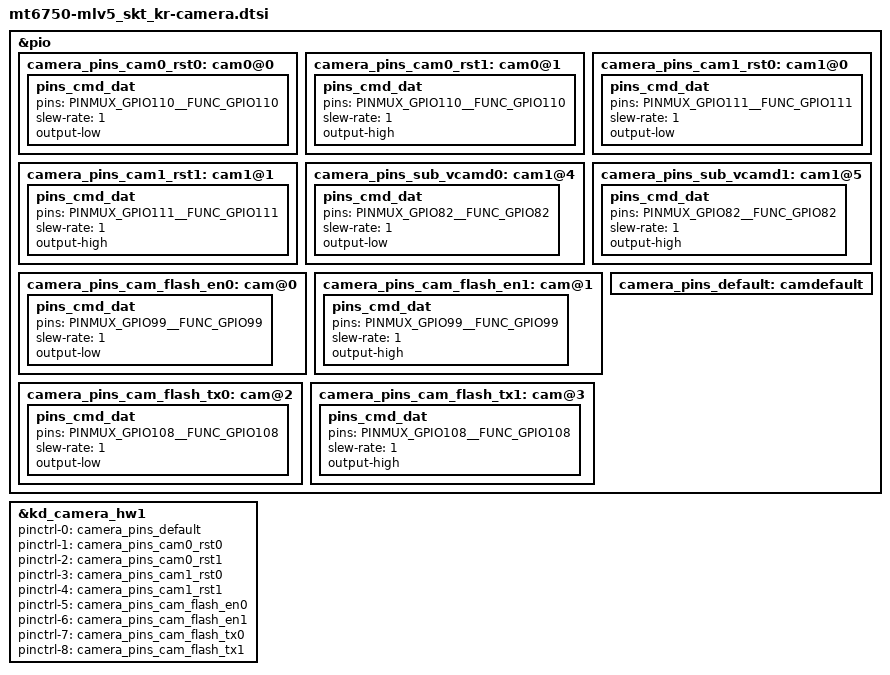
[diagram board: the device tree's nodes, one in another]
/*
 * LG Electronics LV5 usb device tree source
 *
 * Copyright (c) 2016 LG Electronics Co., Ltd.
 *              http://www.lge.com
 *
 */

/* CAMERA GPIO standardization */
&pio {
	camera_pins_cam0_rst0: cam0@0 {
	    pins_cmd_dat {
			pins = <PINMUX_GPIO110__FUNC_GPIO110>;
			slew-rate = <1>; /*direction 0:in, 1:out*/
			output-low;/*direction out used only. output_low or high*/
		};
	};
	camera_pins_cam0_rst1: cam0@1 {
	    pins_cmd_dat {
			pins = <PINMUX_GPIO110__FUNC_GPIO110>;
			slew-rate = <1>;
			output-high;
		};
	};
	camera_pins_cam1_rst0: cam1@0 {
	    pins_cmd_dat {
			pins = <PINMUX_GPIO111__FUNC_GPIO111>;
			slew-rate = <1>; /*direction 0:in, 1:out*/
			output-low;/*direction out used only. output_low or high*/
		};
	};
	camera_pins_cam1_rst1: cam1@1 {
	    pins_cmd_dat {
			pins = <PINMUX_GPIO111__FUNC_GPIO111>;
			slew-rate = <1>;
			output-high;
		};
	};
	camera_pins_sub_vcamd0: cam1@4 {
		pins_cmd_dat {
			pins = <PINMUX_GPIO82__FUNC_GPIO82>;
			slew-rate = <1>;
			output-low;
		};
	};
	camera_pins_sub_vcamd1: cam1@5 {
		pins_cmd_dat {
			pins = <PINMUX_GPIO82__FUNC_GPIO82>;
			slew-rate = <1>;
			output-high;
		};
	};
	camera_pins_cam_flash_en0: cam@0 {
	    pins_cmd_dat {
			pins = <PINMUX_GPIO99__FUNC_GPIO99>;/*GPIO_CAMERA_FLASH_EN_PIN*/
			slew-rate = <1>; /*direction 0:in, 1:out*/
			output-low;/*direction out used only. output_low or high*/
		};
	};
	camera_pins_cam_flash_en1: cam@1 {
	    pins_cmd_dat {
			pins = <PINMUX_GPIO99__FUNC_GPIO99>;/*GPIO_CAMERA_FLASH_EN_PIN*/
			slew-rate = <1>; /*direction 0:in, 1:out*/
			output-high;
		};
	};
	camera_pins_cam_flash_tx0: cam@2 {
	    pins_cmd_dat {
			pins = <PINMUX_GPIO108__FUNC_GPIO108>;/*GPIO_CAMERA_FLASH_TX_PIN*/
			slew-rate = <1>; /*direction 0:in, 1:out*/
			output-low;/*direction out used only. output_low or high*/
		};
	};
	camera_pins_cam_flash_tx1: cam@3 {
	    pins_cmd_dat {
			pins = <PINMUX_GPIO108__FUNC_GPIO108>;/*GPIO_CAMERA_FLASH_TX_PIN*/
			slew-rate = <1>; /*direction 0:in, 1:out*/
			output-high;/*direction out used only. output_low or high*/
		};
	};
	/*camera_pins_cam_ldo_vcama_0: cam@vcama0 {
	};
	camera_pins_cam_ldo_vcama_1: cam@vcama1 {
	};*/
	camera_pins_default: camdefault {
	};

};

&kd_camera_hw1 {
	pinctrl-names = "default",
			"cam0_rst0", "cam0_rst1", "cam1_rst0", "cam1_rst1",
			"cam_flash_en0", "cam_flash_en1", "cam_flash_tx0", "cam_flash_tx1";
	pinctrl-0 = <&camera_pins_default>;
	pinctrl-1 = <&camera_pins_cam0_rst0>;
	pinctrl-2 = <&camera_pins_cam0_rst1>;
	pinctrl-3 = <&camera_pins_cam1_rst0>;
	pinctrl-4 = <&camera_pins_cam1_rst1>;

	pinctrl-5 = <&camera_pins_cam_flash_en0>;
	pinctrl-6 = <&camera_pins_cam_flash_en1>;
	pinctrl-7 = <&camera_pins_cam_flash_tx0>;
	pinctrl-8 = <&camera_pins_cam_flash_tx1>;
	
	status = "okay";

};
/* CAMERA GPIO end */

